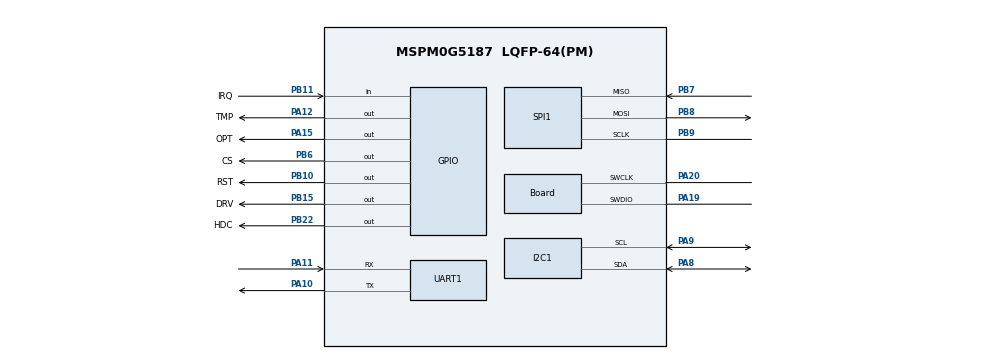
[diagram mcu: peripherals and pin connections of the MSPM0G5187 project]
// UART variant: the same pins plus the backchannel UART (UC0, PA10 TX, PA11 RX, 115200).
// LP-MSPM0G5187 host for the BP-BASSENSORSMKII: I2C on BP pins 9 (PA9 SCL) and 10 (PA8 SDA), ADC on BP pin 2 (PA25),
// power pins: BP pin 6 (PB22, HDC2080, low = on), 27 (PA15, OPT3001, high = on), 28 (PA12, TMP117, high = on), 24 (PB15, DRV5055, low = on)
//@cliArgs --device "MSPM0G518X" --package "LQFP-64(PM)" --part "Default"
//@v2CliArgs --device "MSPM0G5187" --package "LQFP-64(PM)"
// @cliArgs --board /ti/boards/LP_MSPM0G5187 --rtos nortos

const ADC12  = scripting.addModule("/ti/driverlib/ADC12", {}, false);
const ADC121 = ADC12.addInstance();
const Board  = scripting.addModule("/ti/driverlib/Board", {}, false);
const GPIO   = scripting.addModule("/ti/driverlib/GPIO", {}, false);
const GPIO1  = GPIO.addInstance();
const GPIO2  = GPIO.addInstance();
const GPIO3  = GPIO.addInstance();
const GPIO4  = GPIO.addInstance();
const I2C    = scripting.addModule("/ti/driverlib/I2C", {}, false);
const I2C1   = I2C.addInstance();
const SYSCTL = scripting.addModule("/ti/driverlib/SYSCTL");
const UART   = scripting.addModule("/ti/driverlib/UART", {}, false);
const UART1  = UART.addInstance();

ADC121.$name                       = "ADC12_0";
ADC121.sampClkSrc                  = "DL_ADC12_CLOCK_ULPCLK";
ADC121.sampClkDiv                  = "DL_ADC12_CLOCK_DIVIDE_8";
ADC121.sampleTime0                 = "125 us";
ADC121.powerDownMode               = "DL_ADC12_POWER_DOWN_MODE_MANUAL";
ADC121.adcMem0chansel              = "DL_ADC12_INPUT_CHAN_2";
ADC121.peripheral.$assign          = "ADC0";
ADC121.peripheral.adcPin2.$assign  = "PA25";

Board.peripheral.$assign          = "DEBUGSS";
Board.peripheral.swclkPin.$assign = "PA20";
Board.peripheral.swdioPin.$assign = "PA19";

GPIO1.$name                          = "HDC_PWR";
GPIO1.associatedPins[0].$name        = "HDC";
GPIO1.associatedPins[0].initialValue = "SET";
GPIO1.associatedPins[0].pin.$assign  = "PB22";
GPIO2.$name                          = "OPT_PWR";
GPIO2.associatedPins[0].$name        = "OPT";
GPIO2.associatedPins[0].pin.$assign  = "PA15";
GPIO3.$name                          = "TMP_PWR";
GPIO3.associatedPins[0].$name        = "TMP";
GPIO3.associatedPins[0].pin.$assign  = "PA12";
GPIO4.$name                          = "DRV_PWR";
GPIO4.associatedPins[0].$name        = "DRV";
GPIO4.associatedPins[0].initialValue = "SET";
GPIO4.associatedPins[0].pin.$assign  = "PB15";

I2C1.basicEnableController     = true;
I2C1.basicControllerBusSpeed   = 100000;
I2C1.$name                     = "I2C";
I2C1.peripheral.sdaPin.$assign = "PA8";
I2C1.peripheral.sclPin.$assign = "PA9";

UART1.$name                    = "UART_0";
UART1.enableFIFO               = true;
UART1.targetBaudRate           = 115200;
UART1.peripheral.$assign       = "UC0";
UART1.peripheral.rxPin.$assign = "PA11";
UART1.peripheral.txPin.$assign = "PA10";

SYSCTL.forceDefaultClkConfig = true;
SYSCTL.clockTreeEn           = true;

const ProjectConfig              = scripting.addModule("/ti/project_config/ProjectConfig", {}, false);
ProjectConfig.migrationCondition = true;

// ---- CC1407P radio (BP-CC1407P-9-FE beside the board, eight wires) ----
// UC3 as a 3-wire SPI on J20: PB9 SCLK, PB8 PICO, PB7 POCI. Chip select PB6, RESET_N PB10, SPI_INT PB11 (falling edge), all on J20.
const SPI   = scripting.addModule("/ti/driverlib/SPI", {}, false);
const SPI1  = SPI.addInstance();
SPI1.$name                          = "SPI_0";
SPI1.frameFormat                    = "MOTO3";
SPI1.targetBitRate                  = 1000000;
SPI1.peripheral.$assign             = "UC3";
SPI1.peripheral.sclkPin.$assign     = "PB9";
SPI1.peripheral.mosiPin.$assign     = "PB8";
SPI1.peripheral.misoPin.$assign     = "PB7";

const GPIO5 = GPIO.addInstance();
GPIO5.$name                          = "RADIO";
GPIO5.associatedPins.create(2);
GPIO5.associatedPins[0].$name        = "CS";
GPIO5.associatedPins[0].initialValue = "SET";
GPIO5.associatedPins[0].pin.$assign  = "PB6";
GPIO5.associatedPins[1].$name        = "RST";
GPIO5.associatedPins[1].initialValue = "SET";
GPIO5.associatedPins[1].pin.$assign  = "PB10";

const GPIO6 = GPIO.addInstance();
GPIO6.$name                             = "RADIO_INT";
GPIO6.associatedPins[0].$name           = "IRQ";
GPIO6.associatedPins[0].direction       = "INPUT";
GPIO6.associatedPins[0].internalResistor = "PULL_UP";
GPIO6.associatedPins[0].interruptEn     = true;
GPIO6.associatedPins[0].polarity        = "FALL";
GPIO6.associatedPins[0].pin.$assign     = "PB11";
